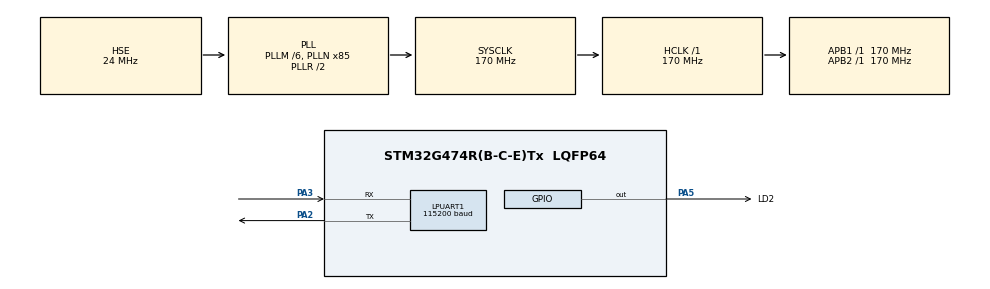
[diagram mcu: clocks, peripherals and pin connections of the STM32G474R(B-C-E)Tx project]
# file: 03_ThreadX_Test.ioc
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LPUART1.BaudRate=115200
Mcu.Family=STM32G4
Mcu.Name=STM32G474R(B-C-E)Tx
Mcu.Package=LQFP64
NVIC.PriorityGroup=NVIC_PRIORITYGROUP_4
PA13.Mode=Serial_Wire
PA13.Signal=SYS_JTMS-SWDIO
PA14.Mode=Serial_Wire
PA14.Signal=SYS_JTCK-SWCLK
PA2.Mode=Asynchronous
PA2.Signal=LPUART1_TX
PA3.Mode=Asynchronous
PA3.Signal=LPUART1_RX
PA5.GPIO_Label=LD2
PA5.Signal=GPIO_Output
PF0-OSC_IN.Mode=HSE-External-Oscillator
PF0-OSC_IN.Signal=RCC_OSC_IN
PF1-OSC_OUT.Mode=HSE-External-Oscillator
PF1-OSC_OUT.Signal=RCC_OSC_OUT
ProjectManager.HeapSize=0x200
ProjectManager.StackSize=0x400
ProjectManager.TargetToolchain=STM32CubeIDE
RCC.ADC12Freq_Value=170000000
RCC.ADC345Freq_Value=170000000
RCC.AHBFreq_Value=170000000
RCC.APB1Freq_Value=170000000
RCC.APB1TimFreq_Value=170000000
RCC.APB2Freq_Value=170000000
RCC.APB2TimFreq_Value=170000000
RCC.CortexFreq_Value=170000000
RCC.EXTERNAL_CLOCK_VALUE=12288000
RCC.HCLKFreq_Value=170000000
RCC.HSE_VALUE=24000000
RCC.HSI48_VALUE=48000000
RCC.HSI_VALUE=16000000
RCC.LSE_VALUE=32768
RCC.PLLM=RCC_PLLM_DIV6
RCC.PLLN=85
RCC.PLLSourceVirtual=RCC_PLLSOURCE_HSE
RCC.SYSCLKFreq_VALUE=170000000
RCC.SYSCLKSource=RCC_SYSCLKSOURCE_PLLCLK
RCC.USBFreq_Value=170000000
RCC.VCOOutputFreq_Value=340000000
VP_SYS_VS_DBSignals.Mode=DisableDeadBatterySignals
board=custom

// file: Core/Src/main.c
/* USER CODE BEGIN Header */
/**
  ******************************************************************************
  * @file           : main.c
  * @brief          : Main program body
  ******************************************************************************
  * @attention
  *
  * Copyright (c) 2025 STMicroelectronics.
  * All rights reserved.
  *
  * This software is licensed under terms that can be found in the LICENSE file
  * in the root directory of this software component.
  * If no LICENSE file comes with this software, it is provided AS-IS.
  *
  ******************************************************************************
  */
/* USER CODE END Header */
#include "main.h"
#include "usart.h"
#include "gpio.h"

/* USER CODE BEGIN Includes */
#include "tx_api.h"
/* USER CODE END Includes */

/* USER CODE BEGIN PD */
#define DEMO_STACK_SIZE         (2 * 1024)
#define DEMO_BYTE_POOL_SIZE     (32 * 1024)

TX_BYTE_POOL            byte_pool_0;

TX_THREAD               thread_0;
TX_THREAD               thread_1;

/* USER CODE END PD */

void SystemClock_Config(void);

/* USER CODE BEGIN 0 */
void thread_0_entry(ULONG thread_input)
{
	ULONG start_ticks, end_ticks, elapsed_ticks;

    while(1)
    {
    	/* 记录任务开始时间 */
    	start_ticks = DWT->CYCCNT;
    	HAL_GPIO_TogglePin(LD2_GPIO_Port, LD2_Pin);  // 翻转LED状态
        /* 记录任务结束时间 */
        end_ticks = DWT->CYCCNT;
        /* 计算耗时（单位：周期数） */
        elapsed_ticks = end_ticks - start_ticks;

        float elapsed_us = (float)elapsed_ticks / 170.00f;

        /* 输出或记录执行时间 */
        printf("Task execution time: %.2f us\n", elapsed_us);
        tx_thread_sleep(300);
    }
}

void thread_1_entry(ULONG thread_input)
{
	const char msg[] = "Hello from ThreadX!\r\n";

    while(1)
    {
    	printf("%s", msg);

        tx_thread_sleep(1000);
    }
}

void tx_application_define(void *first_unused_memory)
{
    CHAR *pointer = TX_NULL;

    /* Create a byte memory pool from which to allocate the thread stacks.  */
    tx_byte_pool_create(&byte_pool_0, "byte pool 0", first_unused_memory, DEMO_BYTE_POOL_SIZE);

    /* Allocate the stack for thread 0.  */
    tx_byte_allocate(&byte_pool_0, (VOID **) &pointer, DEMO_STACK_SIZE, TX_NO_WAIT);
    /* Create the main thread.  */
    tx_thread_create(&thread_0, "thread 0", thread_0_entry, 0,
                    pointer, DEMO_STACK_SIZE,
                    1, 1, TX_NO_TIME_SLICE, TX_AUTO_START);

    /* Allocate the stack for thread 1.  */
    tx_byte_allocate(&byte_pool_0, (VOID **) &pointer, DEMO_STACK_SIZE, TX_NO_WAIT);
    /* Create threads 1  */
    tx_thread_create(&thread_1, "thread 1", thread_1_entry, 0,
                    pointer, DEMO_STACK_SIZE,
                    2, 2, TX_NO_TIME_SLICE, TX_AUTO_START);
}

/* USER CODE END 0 */

int main(void)
{

  /* MCU Configuration--------------------------------------------------------*/

  /* Reset of all peripherals, Initializes the Flash interface and the Systick. */
  HAL_Init();

  /* Configure the system clock */
  SystemClock_Config();

  /* Initialize all configured peripherals */
  MX_GPIO_Init();
  MX_LPUART1_UART_Init();
  /* USER CODE BEGIN 2 */
  tx_kernel_enter();
  /* USER CODE END 2 */

  /* Infinite loop */
  while (1)
  {

  }
}

void SystemClock_Config(void)
{
  RCC_OscInitTypeDef RCC_OscInitStruct = {0};
  RCC_ClkInitTypeDef RCC_ClkInitStruct = {0};

  /** Configure the main internal regulator output voltage
  */
  HAL_PWREx_ControlVoltageScaling(PWR_REGULATOR_VOLTAGE_SCALE1_BOOST);

  /** Initializes the RCC Oscillators according to the specified parameters
  * in the RCC_OscInitTypeDef structure.
  */
  RCC_OscInitStruct.OscillatorType = RCC_OSCILLATORTYPE_HSE;
  RCC_OscInitStruct.HSEState = RCC_HSE_ON;
  RCC_OscInitStruct.PLL.PLLState = RCC_PLL_ON;
  RCC_OscInitStruct.PLL.PLLSource = RCC_PLLSOURCE_HSE;
  RCC_OscInitStruct.PLL.PLLM = RCC_PLLM_DIV6;
  RCC_OscInitStruct.PLL.PLLN = 85;
  RCC_OscInitStruct.PLL.PLLP = RCC_PLLP_DIV2;
  RCC_OscInitStruct.PLL.PLLQ = RCC_PLLQ_DIV2;
  RCC_OscInitStruct.PLL.PLLR = RCC_PLLR_DIV2;
  if (HAL_RCC_OscConfig(&RCC_OscInitStruct) != HAL_OK)
  {
    Error_Handler();
  }

  /** Initializes the CPU, AHB and APB buses clocks
  */
  RCC_ClkInitStruct.ClockType = RCC_CLOCKTYPE_HCLK|RCC_CLOCKTYPE_SYSCLK
                              |RCC_CLOCKTYPE_PCLK1|RCC_CLOCKTYPE_PCLK2;
  RCC_ClkInitStruct.SYSCLKSource = RCC_SYSCLKSOURCE_PLLCLK;
  RCC_ClkInitStruct.AHBCLKDivider = RCC_SYSCLK_DIV1;
  RCC_ClkInitStruct.APB1CLKDivider = RCC_HCLK_DIV1;
  RCC_ClkInitStruct.APB2CLKDivider = RCC_HCLK_DIV1;

  if (HAL_RCC_ClockConfig(&RCC_ClkInitStruct, FLASH_LATENCY_4) != HAL_OK)
  {
    Error_Handler();
  }
}

void Error_Handler(void)
{
  __disable_irq();
  while (1)
  {
  }
}
